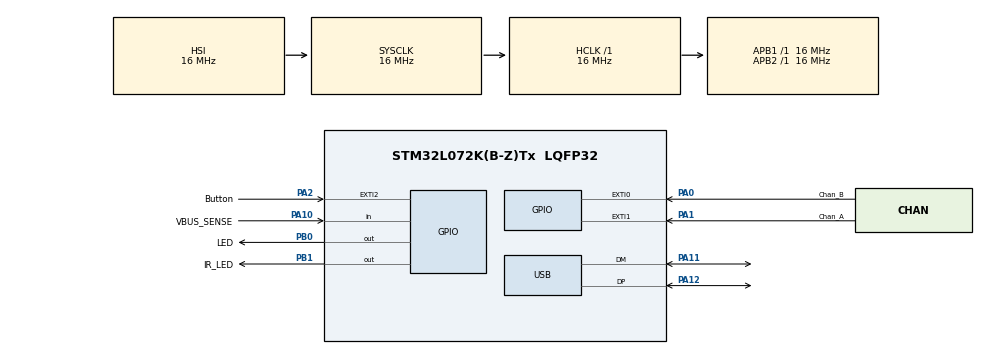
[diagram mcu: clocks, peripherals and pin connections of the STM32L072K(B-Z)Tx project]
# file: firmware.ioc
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Mcu.Family=STM32L0
RCC.MSI_VALUE=2097000
USB_DEVICE.CLASS_NAME_FS=HID
NVIC.USB_IRQn=true\:0\:0\:false\:false\:true\:false\:true
USB_DEVICE.VirtualModeFS=Hid_FS
PA0.GPIO_Label=Chan_B
PA11.Mode=Device
PB0.GPIO_Label=LED
RCC.SYSCLKSource=RCC_SYSCLKSOURCE_HSI
ProjectManager.StackSize=0x400
RCC.HSI48MClockSelection=RCC_USBCLKSOURCE_HSI48
PA13.Signal=SYS_SWDIO
RCC.HSI16_VALUE=16000000
PA12.Signal=USB_DP
ProjectManager.TargetToolchain=STM32CubeIDE
RCC.HCLKFreq_Value=16000000
RCC.APB2TimFreq_Value=16000000
RCC.LSE_VALUE=32768
PA1.Signal=GPXTI1
RCC.AHBFreq_Value=16000000
board=custom
RCC.VCOOutputFreq_Value=48000000
VP_USB_DEVICE_VS_USB_DEVICE_HID_FS.Mode=HID_FS
RCC.APB2Freq_Value=16000000
PA14.Mode=Serial_Wire
PB1.GPIO_Label=IR_LED
RCC.ADCFreq_Value=16000000
PA1.GPIO_Label=Chan_A
PA10.GPIO_Label=VBUS_SENSE
PB7.Signal=SYS_PVD_IN
PA13.Mode=Serial_Wire
Mcu.Name=STM32L072K(B-Z)Tx
PA2.Signal=GPXTI2
PA0.Signal=GPXTI0
RCC.SYSCLKFreq_VALUE=16000000
Mcu.Package=LQFP32
PB1.Signal=GPIO_Output
PA12.Mode=Device
PA2.GPIO_Label=Button
PB7.Mode=Mode_PVD_Ext
PA11.Signal=USB_DM
PA10.Signal=GPIO_Input
PA14.Signal=SYS_SWCLK
ProjectManager.HeapSize=0x200
RCC.HSI_VALUE=16000000
RCC.APB1TimFreq_Value=16000000
RCC.APB1Freq_Value=16000000
PB0.Signal=GPIO_Output
USB_DEVICE.VirtualMode=Hid
RCC.HSI48_VALUE=48000000

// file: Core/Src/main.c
/* USER CODE BEGIN Header */
/**
  ******************************************************************************
  * @file           : main.c
  * @brief          : Main program body
  ******************************************************************************
  * @attention
  *
  * <h2><center>&copy; Copyright (c) 2020 STMicroelectronics.
  * All rights reserved.</center></h2>
  *
  * This software component is licensed by ST under BSD 3-Clause license,
  * the "License"; You may not use this file except in compliance with the
  * License. You may obtain a copy of the License at:
  *                        opensource.org/licenses/BSD-3-Clause
  *
  ******************************************************************************
  */
/* USER CODE END Header */

#include "main.h"
#include "usb_device.h"

/* USER CODE BEGIN Includes */
#include "blink.h"
#include "queue.h"
#include "nec.h"
#include "encoder.h"

/* USER CODE END Includes */

void SystemClock_Config(void);
static void MX_GPIO_Init(void);

int main(void)
{

  /* MCU Configuration--------------------------------------------------------*/

  /* Reset of all peripherals, Initializes the Flash interface and the Systick. */
  HAL_Init();

  /* Configure the system clock */
  SystemClock_Config();

  /* Initialize all configured peripherals */
  MX_GPIO_Init();
  MX_USB_DEVICE_Init();
  /* USER CODE BEGIN 2 */

  Blink_Init();
  DWT_Delay_Init();
  queue_init(&q);
  /* USER CODE END 2 */

  /* Infinite loop */
  /* USER CODE BEGIN WHILE */
  while (1)
  {
	  if(!queue_empty(&q)) {
		  HAL_GPIO_WritePin(GPIOC, GPIO_PIN_13, GPIO_PIN_RESET);
		  nec_send(queue_get(&q));
	  } else {
		  HAL_GPIO_WritePin(GPIOC, GPIO_PIN_13, GPIO_PIN_SET);
	  }
  }
  /* USER CODE END 3 */
}

void SystemClock_Config(void)
{
  RCC_OscInitTypeDef RCC_OscInitStruct = {0};
  RCC_ClkInitTypeDef RCC_ClkInitStruct = {0};
  RCC_PeriphCLKInitTypeDef PeriphClkInit = {0};

  /** Configure the main internal regulator output voltage
  */
  __HAL_PWR_VOLTAGESCALING_CONFIG(PWR_REGULATOR_VOLTAGE_SCALE1);
  /** Initializes the CPU, AHB and APB busses clocks
  */
  RCC_OscInitStruct.OscillatorType = RCC_OSCILLATORTYPE_HSI|RCC_OSCILLATORTYPE_HSI48;
  RCC_OscInitStruct.HSIState = RCC_HSI_ON;
  RCC_OscInitStruct.HSICalibrationValue = RCC_HSICALIBRATION_DEFAULT;
  RCC_OscInitStruct.HSI48State = RCC_HSI48_ON;
  RCC_OscInitStruct.PLL.PLLState = RCC_PLL_NONE;
  if (HAL_RCC_OscConfig(&RCC_OscInitStruct) != HAL_OK)
  {
    Error_Handler();
  }
  /** Initializes the CPU, AHB and APB busses clocks
  */
  RCC_ClkInitStruct.ClockType = RCC_CLOCKTYPE_HCLK|RCC_CLOCKTYPE_SYSCLK
                              |RCC_CLOCKTYPE_PCLK1|RCC_CLOCKTYPE_PCLK2;
  RCC_ClkInitStruct.SYSCLKSource = RCC_SYSCLKSOURCE_HSI;
  RCC_ClkInitStruct.AHBCLKDivider = RCC_SYSCLK_DIV1;
  RCC_ClkInitStruct.APB1CLKDivider = RCC_HCLK_DIV1;
  RCC_ClkInitStruct.APB2CLKDivider = RCC_HCLK_DIV1;

  if (HAL_RCC_ClockConfig(&RCC_ClkInitStruct, FLASH_LATENCY_0) != HAL_OK)
  {
    Error_Handler();
  }
  PeriphClkInit.PeriphClockSelection = RCC_PERIPHCLK_USB;
  PeriphClkInit.UsbClockSelection = RCC_USBCLKSOURCE_HSI48;
  if (HAL_RCCEx_PeriphCLKConfig(&PeriphClkInit) != HAL_OK)
  {
    Error_Handler();
  }
}

static void MX_GPIO_Init(void)
{
  GPIO_InitTypeDef GPIO_InitStruct = {0};

  /* GPIO Ports Clock Enable */
  __HAL_RCC_GPIOA_CLK_ENABLE();
  __HAL_RCC_GPIOB_CLK_ENABLE();

  /*Configure GPIO pin Output Level */
  HAL_GPIO_WritePin(GPIOB, LED_Pin|IR_LED_Pin, GPIO_PIN_RESET);

  /*Configure GPIO pins : Chan_B_Pin Chan_A_Pin Button_Pin */
  GPIO_InitStruct.Pin = Chan_B_Pin|Chan_A_Pin|Button_Pin;
  GPIO_InitStruct.Mode = GPIO_MODE_IT_RISING;
  GPIO_InitStruct.Pull = GPIO_NOPULL;
  HAL_GPIO_Init(GPIOA, &GPIO_InitStruct);

  /*Configure GPIO pins : LED_Pin IR_LED_Pin */
  GPIO_InitStruct.Pin = LED_Pin|IR_LED_Pin;
  GPIO_InitStruct.Mode = GPIO_MODE_OUTPUT_PP;
  GPIO_InitStruct.Pull = GPIO_NOPULL;
  GPIO_InitStruct.Speed = GPIO_SPEED_FREQ_LOW;
  HAL_GPIO_Init(GPIOB, &GPIO_InitStruct);

  /*Configure GPIO pin : VBUS_SENSE_Pin */
  GPIO_InitStruct.Pin = VBUS_SENSE_Pin;
  GPIO_InitStruct.Mode = GPIO_MODE_INPUT;
  GPIO_InitStruct.Pull = GPIO_NOPULL;
  HAL_GPIO_Init(VBUS_SENSE_GPIO_Port, &GPIO_InitStruct);

  /*Configure GPIO pin : PB7 */
  GPIO_InitStruct.Pin = GPIO_PIN_7;
  GPIO_InitStruct.Mode = GPIO_MODE_ANALOG;
  GPIO_InitStruct.Pull = GPIO_NOPULL;
  HAL_GPIO_Init(GPIOB, &GPIO_InitStruct);

}

void Error_Handler(void)
{
}

/************************ (C) COPYRIGHT STMicroelectronics *****END OF FILE****/
